# link_layer_tx_model: IP-XACT component
VLNV IcronTechnologies:IcronTechnologies:link_layer_tx_model:1.0

## Parameters
addr_width = 9
bus_width = 32

## Bus interfaces (logical=physical port)
default_map: slave AGNISYS:AGNISYS:APB:1.0, memory map link_layer_txmap
  pclk=pclk, presetn=presetn, psel=psel, penable=penable, pwrite=pwrite, pprot=pprot, pstrb=pstrb, pwdata=pwdata, paddr=paddr, pready=pready, prdata=prdata, pslverr=pslverr

## Ports
in pclk
in presetn
in psel
in penable
in pwrite
in pprot[2:0]
in pstrb[(bus_width div 8 )-1:0]
in pwdata[bus_width -1:0]
in paddr[addr_width -1:0]
out pready
out prdata[bus_width -1:0]
out pslverr
out link_layer_tx_regsversion_major_r[7:0]
out link_layer_tx_regsversion_minor_r[7:0]
out link_layer_tx_regsversion_patch_r[7:0]
out link_layer_tx_regscontrol_enb
out link_layer_tx_regscontrol_force_xgmii_rf_r
out link_layer_tx_regscontrol_force_xgmii_idle_r
out link_layer_tx_regsmac_mac_config_enb
out link_layer_tx_regsmac_mac_config_inject_crc32_err_r
out link_layer_tx_regsmac_mac_config_disable_crc32_r
out link_layer_tx_regsmac_mac_config_dbg_seq_num_en_r
out link_layer_tx_regsmac_mac_config_en_r
out link_layer_tx_regsmac_pa_word1_enb
out link_layer_tx_regsmac_pa_word1_pa_word1_r[23:0]
out link_layer_tx_regsmac_pa_word0_enb
out link_layer_tx_regsmac_pa_word0_pa_word0_r[31:0]
out link_layer_tx_regsmac_sfd_enb
out link_layer_tx_regsmac_sfd_sfd_r[7:0]
out link_layer_tx_regsmac_da_word1_enb
out link_layer_tx_regsmac_da_word1_da_w1_r[15:0]
out link_layer_tx_regsmac_da_word0_enb
out link_layer_tx_regsmac_da_word0_da_w0_r[31:0]
out link_layer_tx_regsmac_sa__word1_enb
out link_layer_tx_regsmac_sa__word1_sa_w1_r[15:0]
out link_layer_tx_regsmac_sa_word0_enb
out link_layer_tx_regsmac_sa_word0_sa_w0_r[31:0]
out link_layer_tx_regsmac_lt_enb
out link_layer_tx_regsmac_lt_lt_mode_r
out link_layer_tx_regsmac_lt_lt_r[15:0]
out link_layer_tx_regsmac_idle_enb
out link_layer_tx_regsmac_idle_idle_r[7:0]
out link_layer_tx_regsmac_frm_rate_enb
out link_layer_tx_regsmac_frm_rate_frm_rate_r[11:0]
out link_layer_tx_regsmac_bandwidth_gap_enb
out link_layer_tx_regsmac_bandwidth_gap_bandwidth_gap_r[31:0]
out link_layer_tx_regsmac_bandwidth_limit_enb
out link_layer_tx_regsmac_bandwidth_limit_bandwidth_limit_r[31:0]
out link_layer_tx_regsmac_stats0_rd2clr_config_rd_valid_out
out link_layer_tx_regsmac_stats0_rd2clr_config_wr_valid_out
out link_layer_tx_regsmac_stats0_pause_frame_rd_valid_out
out link_layer_tx_regsmac_stats0_out_eop_rd_valid_out
out link_layer_tx_regsmac_stats0_out_sop_rd_valid_out
out link_layer_tx_regsmac_stats0_stall_ptp_in_rd_valid_out
out link_layer_tx_regsmac_stats0_in_eop_rd_valid_out
out link_layer_tx_regsmac_stats0_in_sop_rd_valid_out
out link_layer_tx_regsmac_stats0_fsm_count_beyond_ptp_rd_valid_out
out link_layer_tx_regsmac_stats0_fsm_rollover_rd_valid_out
out link_layer_tx_regsmedia_rs_enable_enb
out link_layer_tx_regsmedia_rs_enable_tx_xgmii_en_r
out link_layer_tx_regsmedia_rs_enable_tx_gmii_en_r
out link_layer_tx_regsmedia_rs_pfifo_write_engine_config0_clear_enb
out link_layer_tx_regsmedia_rs_pfifo_write_engine_config0_clear_wclr_r
out link_layer_tx_regsmedia_rs_pfifo_write_engine_config0_mode_enb
out link_layer_tx_regsmedia_rs_pfifo_write_engine_config0_mode_drp_on_sop_r
out link_layer_tx_regsmedia_rs_pfifo_write_engine_config0_mode_drp_on_pkt_err_r
out link_layer_tx_regsmedia_rs_pfifo_write_engine_config0_mode_pkt_strm_r
out link_layer_tx_regsmedia_rs_pfifo_write_engine_config0_mode_flw_ctrl_en_r
out link_layer_tx_regsmedia_rs_pfifo_write_engine_config0_notify_limit_enb
out link_layer_tx_regsmedia_rs_pfifo_write_engine_config0_notify_limit_ntfy_lmt_r[31:0]
out link_layer_tx_regsmedia_rs_pfifo_write_engine_stats0_rd2clr_config_rd_valid_out
out link_layer_tx_regsmedia_rs_pfifo_write_engine_stats0_rd2clr_config_wr_valid_out
out link_layer_tx_regsmedia_rs_pfifo_write_engine_stats0_nfifo_dcount_rd_valid_out
out link_layer_tx_regsmedia_rs_pfifo_write_engine_stats0_pfifo_dcount_rd_valid_out
out link_layer_tx_regsmedia_rs_pfifo_write_engine_stats0_pkt_max_byte_cnt_err_rd_valid_out
out link_layer_tx_regsmedia_rs_pfifo_write_engine_stats0_fifo_full_err_rd_valid_out
out link_layer_tx_regsmedia_rs_pfifo_write_engine_stats0_pkt_err_rd_valid_out
out link_layer_tx_regsmedia_rs_pfifo_write_engine_stats0_pkt_sop_err_rd_valid_out
out link_layer_tx_regsmedia_rs_pfifo_write_engine_stats0_wflush_act_rd_valid_out
out link_layer_tx_regsmedia_rs_pfifo_write_engine_stats0_drp_pkt_rd_rd_valid_out
out link_layer_tx_regsmedia_rs_pfifo_write_engine_stats0_drp_pkt_wr_rd_valid_out
out link_layer_tx_regsmedia_rs_pfifo_write_engine_stats0_flow_ctrl_rd_valid_out
out link_layer_tx_regsmedia_rs_pfifo_read_engine_config0_clear_enb
out link_layer_tx_regsmedia_rs_pfifo_read_engine_config0_clear_rclr_r
out link_layer_tx_regsmedia_rs_pfifo_read_engine_stats0_rd2clr_config_rd_valid_out
out link_layer_tx_regsmedia_rs_pfifo_read_engine_stats0_rd2clr_config_wr_valid_out
out link_layer_tx_regsmedia_rs_pfifo_read_engine_stats0_rflush_act_rd_valid_out
out link_layer_tx_regsmedia_rs_pfifo_read_engine_stats0_drp_pkt_rd_valid_out
out link_layer_tx_regsmedia_rs_pfifo_read_engine_stats0_flow_ctrl_rd_valid_out
out link_layer_tx_regsmedia_rs_stats{n}_rd2clr_config_rd_valid_out (n=0..2)
out link_layer_tx_regsmedia_rs_stats{n}_rd2clr_config_wr_valid_out (n=0..2)
out link_layer_tx_regsmedia_rs_stats0_inbuff_eop_rd_valid_out
out link_layer_tx_regsmedia_rs_stats0_inbuff_sop_rd_valid_out
out link_layer_tx_regsmedia_rs_stats1_gmii_outbuff_eop_rd_valid_out
out link_layer_tx_regsmedia_rs_stats1_gmii_outbuff_sop_rd_valid_out
out link_layer_tx_regsmedia_rs_stats1_gmii_done_rd_valid_out
out link_layer_tx_regsmedia_rs_stats1_gmii_start_rd_valid_out
out link_layer_tx_regsmedia_rs_stats2_xgmii_outbuff_eop_rd_valid_out
out link_layer_tx_regsmedia_rs_stats2_xgmii_outbuff_sop_rd_valid_out
out link_layer_tx_regsmedia_rs_stats2_xgmii_done_rd_valid_out
out link_layer_tx_regsmedia_rs_stats2_xgmii_start_rd_valid_out
out link_layer_tx_regsptp_guard_config0_fix_ptp_violations_enb
out link_layer_tx_regsptp_guard_config0_fix_ptp_violations_activate_r
out link_layer_tx_regsptp_guard_config0_max_cycles_enb
out link_layer_tx_regsptp_guard_config0_max_cycles_max_cycle_mode_r[3:0]
out link_layer_tx_regsptp_guard_config0_max_cycles_max_cycles_r[15:0]
out link_layer_tx_regsptp_guard_stats0_rd2clr_config_rd_valid_out
out link_layer_tx_regsptp_guard_stats0_rd2clr_config_wr_valid_out
out link_layer_tx_regsptp_guard_stats0_missing_sop_err_rd_valid_out
out link_layer_tx_regsptp_guard_stats0_missing_eop_err_rd_valid_out
out link_layer_tx_regsptp_guard_stats0_max_cycle_err_rd_valid_out
out link_layer_tx_regsself_test_support_set_up_enb
out link_layer_tx_regsself_test_support_set_up_enable_r
out link_layer_tx_regsself_test_support_media_gen_mca_mgen_enb
out link_layer_tx_regsself_test_support_media_gen_mca_mgen_iwg_cnt_r[1:0]
out link_layer_tx_regsself_test_support_media_gen_mca_mgen_ifg_cnt_r[1:0]
out link_layer_tx_regsself_test_support_media_gen_mca_mgen_pkt_cnt_r[1:0]
out link_layer_tx_regsself_test_support_media_gen_mca_mgen_pkt_size_r[1:0]
out link_layer_tx_regsself_test_support_media_gen_mca_mgen_throttle_r
out link_layer_tx_regsself_test_support_media_gen_mca_mgen_mode_r
out link_layer_tx_regsself_test_support_media_gen_mca_mgen_enable_r
out link_layer_tx_regsself_test_support_media_gen_mca_mgen_go_r
out link_layer_tx_regsself_test_support_framer_max_byte_enb
out link_layer_tx_regsself_test_support_framer_max_byte_max_byte_r[13:0]
out link_layer_tx_regsself_test_support_framer_mac_dg_type_enb
out link_layer_tx_regsself_test_support_framer_mac_dg_type_mac_dg_type_r[7:0]
out link_layer_tx_regsself_test_support_framer_timer_wait_enb
out link_layer_tx_regsself_test_support_framer_timer_wait_timer_wait_r[11:0]
out link_layer_tx_regsself_test_support_framer_mtu_size_enb
out link_layer_tx_regsself_test_support_framer_mtu_size_mtu_size_r[13:0]

## Address spaces and blocks
link_layer_txmap.link_layer_tx: base 0x000, range 0x200, width 32

## Registers
Registers are 32-bit, read-only, reset 0x0 unless marked. A register's access mark holds for its fields unless they carry their own. Offsets are from the block's base; lines under a group give offsets from that group; [hi:lo] are bit positions; {n}, {i} and the like mark numbered series; 'fields as' and 'values as' point back to an identical list; <NAME> marks a mode.

## link_layer_txmap.link_layer_tx — Link Layer TX Registers
Base 0x00000000
0x00 version reset 0x50400 — 5.1.0: Added registers to disable/enable CRC32. And also to inject CRC32 errors 5.2.0: Changed the Interrupt Pending to avoid blocking the register update when enable is 0 5.3.0: Added pending_irq register 5.4.0: Changed Logic to Wire in ift_xgmii and ift_gmii
  [23:16] major — Major version
  [15:8] minor — Minor version
  [7:0] patch — Patch version
0x04 mac group
  0x00 version reset 0x20100 — 2.1.0: Added registers to disable/enable CRC32. And also to inject CRC32 errors
    fields as version
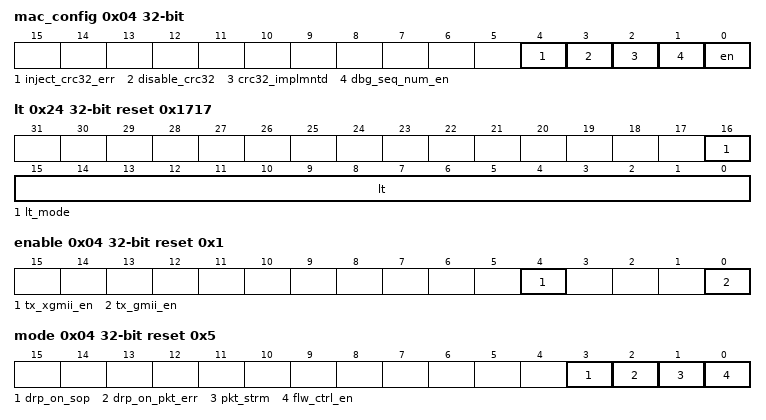
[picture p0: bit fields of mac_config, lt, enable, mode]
  0x04 mac_config access per field
    [4] inject_crc32_err rw — Assert high to ask the logic to insert one crc32 error when CRC32 logic is implemented. Write a 1 and HW clears it when completed the action
    [3] disable_crc32 rw — When set to 1, and if the CRC32 logic is implemented, disables inclusion of correct CRC32.
    [2] crc32_implmntd ro — This is the synthesis parameter value used for CRC32 logic implementation. When 1, it shows the CRC32 logic has been implemented in the logic. Note that, typically CRC32 MUST be implemented in MAC. However, due to some timing issues, we may decide to not have the logic when the system is used in a point-to-point configuration.
    [1] dbg_seq_num_en rw — When set to 1 it enables the debug logic to insert consecutive sequence numbers in the frame. Typically, this and the corresponding register in the RX path should be configured before any traffic sent between the TX and RX. Otherwise, there will not be synchrony between the sent and expected sequence numbers for at least one time
    [0] en rw — When set to 1 it enables the block. NOT USED.
  0x08 pa_word1 rw reset 0x555555
    [23:0] pa_word1 — Preamble values (upper 3 bytes)
  0x0C pa_word0 rw reset 0x55555555
    [31:0] pa_word0 — Preamble values (lower 4 bytes)
  0x10 sfd rw reset 0xD5
    [7:0] sfd — The Start of Frame Delimiter (SFD)
  0x14 da_word1 rw reset 0xDADA — Destination Address Word1
    [15:0] da_w1 — This is the MAC Destination address (upper 2 bytes [47:32])
  0x18 da_word0 rw reset 0xDADADADA — Destination Address Word0
    [31:0] da_w0 — This is the MAC Destination address (lower 4 bytes [31:0])
  0x1C sa__word1 rw reset 0x5A5A — Source Address Word1
    [15:0] sa_w1 — This is the MAC Source address (upper 2 bytes [47:32])
  0x20 sa_word0 rw reset 0x5A5A5A5A — Source Address Word0
    [31:0] sa_w0 — This is the MAC Source address (lower 4 bytes [31:0])
  0x24 lt rw reset 0x1717 — Length/Type Filter
    [16] lt_mode — When 0: The LT field is to be the Length of the payload When 1: The LT field is to be the Type of the payload
    [15:0] lt — This is the MAC type
  0x28 idle rw reset 0x1E
    [7:0] idle — Idle character
  0x2C frm_rate rw — The extra gap (in addition to the mandatory gap) between each Ethernet frame allowing a fine control of the data throughput on the link.
    [11:0] frm_rate — This is the number of idle clock cycles inserted between the frames. For each implementation, it will add frm_rate*bus_size number of MAC bits.
  0x30 bandwidth_gap rw — This is the number of idle clock cycles inserted after a specified number of data words (equal to the clock cycles that has data) are reached. For each implementation, it will add bandwidth_gap*bus_size number of MAC bits.
  0x34 bandwidth_limit rw — This is the number of data words (equal to the clock cycles that has data) that needs to be reached before Bandwidth Gap can be inserted.
  0x38 stats0 group — All the Statistic Registers and their configuration.
    0x00 rd2clr_config rw — Configures if the stats register read by s/w clears the read register. A 1 in any bit configures the h/w to clear the corresponding stats register after a s/w read of that stats register.
      [7] fsm_rollover, [6] fsm_count_beyond_ptp, [5] in_sop, [4] in_eop, [3] stall_ptp_in, [2] out_sop, [1] out_eop, [0] pause_frame
    0x04 pause_frame — Count of pause frames transmitted
    0x08 out_eop — Count of the PTP EOP seen on the output port to the RS
    0x0C out_sop — Count of the PTP SOP seen on the output port to the RS
    0x10 stall_ptp_in — Count of cycles the MAC input is stalled
    0x14 in_eop — Count of the EOP of the PTP packets seen from the clients and after the input stall logic
    0x18 in_sop — Count of the EOP of the PTP packets seen from the clients and after the input stall logic
    0x1C fsm_count_beyond_ptp — Count of the number of cycles the FSM has been beyond the permissible maximum value. This indicates an error in the function of this block
      [7:0] fsm_count_beyond_ptp
    0x20 fsm_rollover — Count of the number of times the input FSM rolled over. This indicates an error in the function of this block
      [7:0] fsm_rollover
0x60 media_rs group — Registers needed for the Media RS in the TX Path
  0x00 version reset 0x10000
    fields as version
  0x04 enable rw reset 0x1
    [4] tx_xgmii_en — When 1, and tx_xgmii_en is 0, it enables the XGMII path
    [0] tx_gmii_en — When 1, and tx_xgmii_en is 0, it enables the GMII path
  0x08 pfifo group
    0x00 version reset 0x10100 — Version 1.1.0: Added Icron Attributes for stats script generation
      fields as version
    0x04 write_engine group
      0x00 config0 group
        0x00 clear rw — Synchronous clear for the write clock domain
          [0] wclr
        0x04 mode rw reset 0x5
          [3] drp_on_sop — When set, drops the current packet without writing it to the buffer. See Wiki
          [2] drp_on_pkt_err — When set, removes the packet from the buffer without presenting it to the output interface upon the ERR bit being set before the notification point. See Wiki
          [1] pkt_strm — Selects packet based or streaming based behavior. See Wiki
          [0] flw_ctrl_en — Enables the flow control. See Wiki
        0x08 notify_limit rw
          [31:0] ntfy_lmt — Sets the number of words required to be written into the packet FIFO before a notification will be generated. See wiki
      0x0C stats0 group — All the Statistic Registers and their configuration for the Write Engine
        0x00 rd2clr_config rw — Configures if the stats register read by s/w clears the read register. A 1 in any bit configures the h/w to clear the corresponding stats register after a s/w read of that stats register.
          [9] flow_ctrl, [8] drp_pkt_wr, [7] drp_pkt_rd, [6] wflush_act, [5] pkt_sop_err, [4] pkt_err, [3] fifo_full_err, [2] pkt_max_byte_cnt_err, [1] pfifo_dcount, [0] nfifo_dcount
        0x04 nfifo_dcount — Current level for the notification FIFO in the PFIFO
          [15:0] nfifo_dcount — _icron_water_marker_ _icron_no_counter_
        0x08 pfifo_dcount — Current level for the packet FIFO in the PFIFO
          [15:0] pfifo_dcount — _icron_water_marker_ _icron_no_counter_
        0x0C pkt_max_byte_cnt_err — The count for capped packets in PFIFO write engine, as the result of reaching maximum size in the PFIFO
          [7:0] pkt_max_byte_cnt_err
        0x10 fifo_full_err — The count for either of PFIFO or NFIFO being full
          [7:0] fifo_full_err
        0x14 pkt_err — The count of packets tagged to be dropped later in the PFIFO read engine
          [7:0] pkt_err
        0x18 pkt_sop_err — The count of packets flushed in the PFIFO during the SOP phase
          [7:0] pkt_sop_err
        0x1C wflush_act — The count of capped packets in the PFIFO. Note that back-to-back packets are counted as one if they are both capped.
          [7:0] wflush_act — _icron_event_detect_rising_edge_
        0x20 drp_pkt_rd — The count of drop packets flagged to be dropped by the read engine
          [7:0] drp_pkt_rd
        0x24 drp_pkt_wr — The count of drop packets by the write engine
          [7:0] drp_pkt_wr
        0x28 flow_ctrl — The count of the clock cycles the DRDY is asserted low resulting in flow control
          [15:0] flow_ctrl
    0x3C read_engine group
      0x00 config0 group
        0x00 clear rw — Synchronous clear for the read clock domain
          [0] rclr
      0x04 stats0 group — All the Statistic Registers and their configuration for the Read Engine
        0x00 rd2clr_config rw — Configures if the stats register read by s/w clears the read register. A 1 in any bit configures the h/w to clear the corresponding stats register after a s/w read of that stats register.
          [2] flow_ctrl, [1] drp_pkt, [0] rflush_act
        0x04 rflush_act — The counts of number of packets flushed from the PFIFO.
          [7:0] rflush_act — _icron_event_detect_rising_edge_
        0x08 drp_pkt — The counts of drop packet in the PFIFO read engine
          [7:0] drp_pkt
        0x0C flow_ctrl — The count of the clock cycles the DRDY is asserted low resulting in flow control
          [15:0] flow_ctrl
  0x58 stats0 group — All the Statistic Registers and their configuration for the GMII
    0x00 rd2clr_config rw — Configures if the stats register read by s/w clears the read register. A 1 in any bit configures the h/w to clear the corresponding stats register after a s/w read of that stats register.
      [1] inbuff_sop, [0] inbuff_eop
    0x04 inbuff_eop — Count of the PTP EOP saved into the buffer
    0x08 inbuff_sop — Count of the PTP SOP saved into the buffer
  0x64 stats1 group — All the Statistic Registers and their configuration for the GMII
    0x00 rd2clr_config rw — Configures if the stats register read by s/w clears the read register. A 1 in any bit configures the h/w to clear the corresponding stats register after a s/w read of that stats register.
      [3] gmii_start, [2] gmii_done, [1] gmii_outbuff_sop, [0] gmii_outbuff_eop
    0x04 gmii_outbuff_eop — Count of the PTP EOP after the buffer and seen on the GMII output port
      [31:0] gmii_out_eop
    0x08 gmii_outbuff_sop — Count of the PTP SOP after the buffer and seen on the GMII output port
    0x0C gmii_done — Count of the GMII FSM completing a packet and after an IFG period is also completed
    0x10 gmii_start — Count of the GMII FSM starting to process a packet
  0x78 stats2 group — All the Statistic Registers and their configuration for the XGMII
    0x00 rd2clr_config rw — Configures if the stats register read by s/w clears the read register. A 1 in any bit configures the h/w to clear the corresponding stats register after a s/w read of that stats register.
      [3] xgmii_start, [2] xgmii_done, [1] xgmii_outbuff_sop, [0] xgmii_outbuff_eop
    0x04 xgmii_outbuff_eop — Count of the PTP EOP after the buffer and seen on the XGMII output port
      [31:0] xgmii_out_eop
    0x08 xgmii_outbuff_sop — Count of the PTP SOP after the buffer and seen on the XGMII output port
    0x0C xgmii_done — Count of the XGMII FSM completing a packet and after an IFG period is also completed
    0x10 xgmii_start — Count of the XGMII FSM starting to process a packet
0xEC ptp_guard group
  0x00 version reset 0x30300 — 3.1.0: Fixed bug in Max Cycle Error where in certain mode the cycles were included in the count 3.2.0: Changed the Interrupt Pending to avoid blocking the register update when enable is 0 3.3.0: Added pending_irq register
    fields as version
  0x04 config0 group
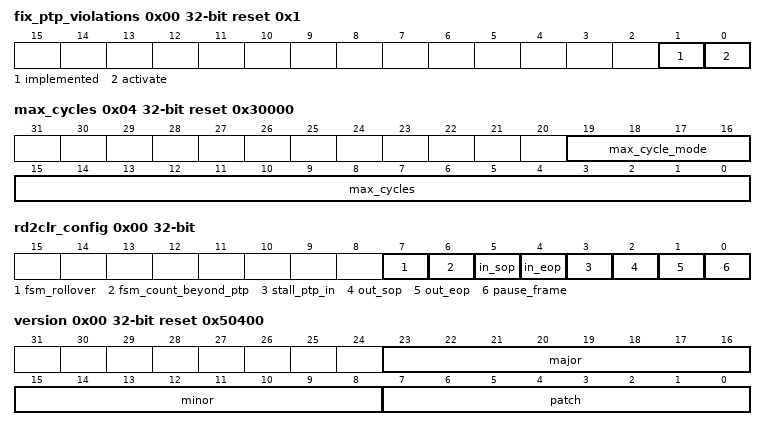
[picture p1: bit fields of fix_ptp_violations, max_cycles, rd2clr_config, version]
    0x00 fix_ptp_violations access per field reset 0x1
      [1] implemented ro — This is the synthesis parameter value used. When 1, it shows the PTP Guard fix logic has been implemented
      [0] activate rw — When 1, and if the fix logic is implemented, it instructs the PTP Guard to fix the PTP violations it detects (and reports). Note that there is a synthesis parameter to generate the "fix" logic or not When 0, no attempt is done to fix (even if the logic exists) and the PTP Guard will only work as a monitor and reports the violations detected. For full details of the operation, what violations are detected and fixed, and how the fix is done, see the wiki.
    0x04 max_cycles rw reset 0x30000
      [19:16] max_cycle_mode — This configures the mode of counting towards max_cycles: 0x0: All PTP cycles are included in the count 0x1: PTP cycles with backpressure (drdy=1'b0) are excluded from the count 0x2: PTP cycles with wait (srdy=1'b0) are excluded from the count 0x3: PTP cycles with either backpressure or wait are excluded from the count. Hence, only "absorbed" PTP cycles are included in the count Other mode values are reserved
      [15:0] max_cycles — Sets the maximum number of clock cycles the PTP packet can last between its sop and eop taking into account the max_cycle_mode When set to 0, it instructs the logic not to fix this violation (when the fix logic is available). However, the monitor will still issue a violation when the cycle count reaches its maximum and rollover.
  0x0C stats0 group — All the Statistic Registers and their configuration
    0x00 rd2clr_config rw — Configures if the stats register read by s/w clears the read register. A 1 in any bit configures the h/w to clear the corresponding stats register after a s/w read of that stats register.
      [2] max_cycle_err, [1] missing_eop_err, [0] missing_sop_err
    0x04 missing_sop_err — Counts the number of PTP violations due to missing sop where the srdy was asserted without a prior sop assertion
      [15:0] missing_sop_err
    0x08 missing_eop_err — Counts the number of PTP violations due to missing eop where the PTP had been started but a new sop is seen without ending the previously started PTP
      [15:0] missing_eop_err
    0x0C max_cycle_err — Counts the number of PTP violations due to reaching the maximum allowed cycles after starting a new PTP
      [15:0] max_cycle_err
  0x1C irq0 group — Define the IRQ group
    0x00 enable rw — The enable for the actual interrupt signals. Writing a 1 enables the interrupt.
      [2] max_cycle_err — Fires on PTP violations due to reaching the maximum allowed cycles after starting a new PTP
      [1] missing_eop_err — Fires on PTP violations due to missing eop where the PTP had been started but a new sop is seen without ending the previously started PTP
      [0] missing_sop_err — Fires on PTP violations due to missing sop where the srdy was asserted without a prior sop assertion
    0x04 pending rw — The actual interrupt(s) that has triggered. Write a 1 to clear.
      [2] max_cycle_err write-1-clears, [1] missing_eop_err write-1-clears, [0] missing_sop_err write-1-clears
    0x08 pending_irq — Registered version of pending & enable.
      [2] max_cycle_err, [1] missing_eop_err, [0] missing_sop_err
    0x0C raw — The status registered values for the interrupt signals, if applicable.
      [2] max_cycle_err — Not used
      [1] missing_eop_err — Not used
      [0] missing_sop_err — Not used
0x118 self_test_support group
  0x00 set_up rw reset 0x1
    [0] enable — Connects CH0 to the self-test logic when it is 0x1, provided the proper parameter (p_impl_self_test) is set to "YES"
  0x04 media_gen group — Registers needed for the Media Generator needed for self-test
    0x00 version reset 0x10000
      fields as version
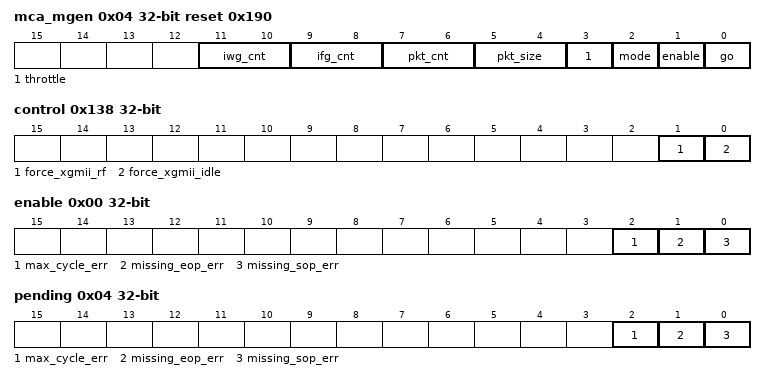
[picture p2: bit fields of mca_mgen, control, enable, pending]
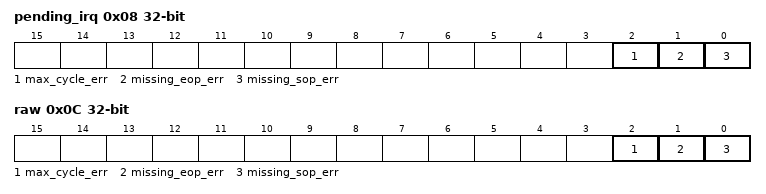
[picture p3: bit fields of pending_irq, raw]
    0x04 mca_mgen rw reset 0x190 — Media generator configuration register
      [11:10] iwg_cnt — Media generator inter-word count select. This is the number of srdy "not ready" (srdy = 1'b0) cycles that can be inserted between words. 0 = 0 cycles 1 = 1 cycle 2 = 2 cycles 3 = 0-3 cycles
      [9:8] ifg_cnt — Media generator inter-frame count select. This is the number of clock cycles that can be inserted between packets. 0 = 0 cycles 1 = 1 cycle 2 = 1023 cycles 3 = rdm 1-1023 cycles
      [7:6] pkt_cnt — Media generator packet count select. 0 = constant - set ConfigMgenX.Go='0' to stop. 1 = 1 time 2 = 1024 times 3 = 65535 times
      [5:4] pkt_size — Media generator packet size select. 0 = fix 10 bytes 1 = fix 1000 bytes 2 = inc 1-1023 bytes 3 = rdm 1-1023 bytes
      [3] throttle — Media generator throttle enable. Allows CPU to control media generator transmitter source ready (srdy). 0 = srdy with/without drdy (may cause loss of traffic) 1 = srdy with drdy
      [2] mode — Media generator traffic mode select. 0 = incrementing data 1 = random data
      [1] enable — Media generator enable. Must be set '0' if the corresponding media is trying to connect to the pipe. Can also be set '0' to stop a media generator that is set for continuous mode. Set '1' if setting go '1'. 0 = disabled 1 = enabled
      [0] go — Go/Busy (Cleared by HW)
  0x0C framer group
    0x00 max_byte rw reset 0x80 — Maximum bytes in incoming PTP bytes
      [13:0] max_byte
    0x04 mac_dg_type rw reset 0x4 — MAC Datagram Type used in the out PTP
      [7:0] mac_dg_type
    0x08 timer_wait rw — Maximum number of clock cycles that is allowed to hold a new incoming PTP before it is put into a MAC Datagram if the input PTPs are not back-to-back and the downstream is not busy. The timer starts when a new PTP is received. This timer gives a control of aggregating input PTPs that are gapped. Note: A value of 0x0 instructs the logic to not wait for input PTPs if they are gapped, unless the downstream is busy in which case the logic will always wait for gapped input PTPs unless the next PTP has the "potential" to go over the MTU size
      [11:0] timer_wait
    0x0C mtu_size rw reset 0x5DC — This is the MTU size to use. Note that the FPGA build must have been built with the highest of normal MTU=1500 or Jumbo MTU=9000 (see max_mtu_size). Accordingly, this value should be less than that.
      [13:0] mtu_size
    0x10 max_mtu_size reset 0x5DC — This is the MTU size used during the FPGA build.
      [13:0] max_mtu_size
0x138 control rw
  [1] force_xgmii_rf — Instructs the Link Layer TX to send Remote Fault order-set on the XGMII. This control provides a back-door to Link Fault Signaling that is normally taken care of by the FPGA, and is mutually exclusive with force_xgmii_idle.
  [0] force_xgmii_idle — Instructs the Link Layer TX to send Idle Character on the XGMII. This control provides a back-door to Link Fault Signaling that is normally taken care of by the FPGA, and is mutually exclusive with force_xgmii_rf.
0x13C irq0 group — Define the IRQ group
  0x00 enable rw — Indicating a rollover for that particular count has occurred
    [28] mac_pause_frame_irq_rollover, [27] mac_out_eop_irq_rollover, [26] mac_out_sop_irq_rollover, [25] mac_stall_ptp_in_irq_rollover, [24] mac_in_eop_irq_rollover, [23] mac_in_sop_irq_rollover, [22] mac_fsm_count_beyond_ptp_irq_rollover, [21] mac_fsm_rollover_irq_rollover, [20] rs_nfifo_dcount_irq_rollover, [19] rs_pfifo_dcount_irq_rollover, [18] rs_pkt_max_byte_cnt_err_irq_rollover, [17] rs_fifo_full_err_irq_rollover, [16] rs_pkt_err_irq_rollover, [15] rs_pkt_sop_err_irq_rollover, [14] rs_wflush_act_irq_rollover, [13] rs_drp_pkt_rd_irq_rollover, [12] rs_drp_pkt_wr_irq_rollover, [11] rs_rflush_act_irq_rollover, [10] rs_drp_pkt_irq_rollover, [9] rs_inbuff_eop_irq_rollover, [8] rs_inbuff_sop_irq_rollover, [7] rs_gmii_outbuff_eop_irq_rollover, [6] rs_gmii_outbuff_sop_irq_rollover, [5] rs_gmii_done_irq_rollover, [4] rs_gmii_start_irq_rollover, [3] rs_xgmii_outbuff_eop_irq_rollover, [2] rs_xgmii_outbuff_sop_irq_rollover, [1] rs_xgmii_done_irq_rollover, [0] rs_xgmii_start_irq_rollover
  0x04 pending rw — Indicating a rollover for that particular count has occurred
    [28] mac_pause_frame_irq_rollover write-1-clears, [27] mac_out_eop_irq_rollover write-1-clears, [26] mac_out_sop_irq_rollover write-1-clears, [25] mac_stall_ptp_in_irq_rollover write-1-clears, [24] mac_in_eop_irq_rollover write-1-clears, [23] mac_in_sop_irq_rollover write-1-clears, [22] mac_fsm_count_beyond_ptp_irq_rollover write-1-clears, [21] mac_fsm_rollover_irq_rollover write-1-clears, [20] rs_nfifo_dcount_irq_rollover write-1-clears, [19] rs_pfifo_dcount_irq_rollover write-1-clears, [18] rs_pkt_max_byte_cnt_err_irq_rollover write-1-clears, [17] rs_fifo_full_err_irq_rollover write-1-clears, [16] rs_pkt_err_irq_rollover write-1-clears, [15] rs_pkt_sop_err_irq_rollover write-1-clears, [14] rs_wflush_act_irq_rollover write-1-clears, [13] rs_drp_pkt_rd_irq_rollover write-1-clears, [12] rs_drp_pkt_wr_irq_rollover write-1-clears, [11] rs_rflush_act_irq_rollover write-1-clears, [10] rs_drp_pkt_irq_rollover write-1-clears, [9] rs_inbuff_eop_irq_rollover write-1-clears, [8] rs_inbuff_sop_irq_rollover write-1-clears, [7] rs_gmii_outbuff_eop_irq_rollover write-1-clears, [6] rs_gmii_outbuff_sop_irq_rollover write-1-clears, [5] rs_gmii_done_irq_rollover write-1-clears, [4] rs_gmii_start_irq_rollover write-1-clears, [3] rs_xgmii_outbuff_eop_irq_rollover write-1-clears, [2] rs_xgmii_outbuff_sop_irq_rollover write-1-clears, [1] rs_xgmii_done_irq_rollover write-1-clears, [0] rs_xgmii_start_irq_rollover write-1-clears
  0x08 pending_irq — Registered version of pending & enable
    fields as irq0.enable
  0x0C raw — Indicating a rollover for that particular count has occurred
    fields as irq0.enable
